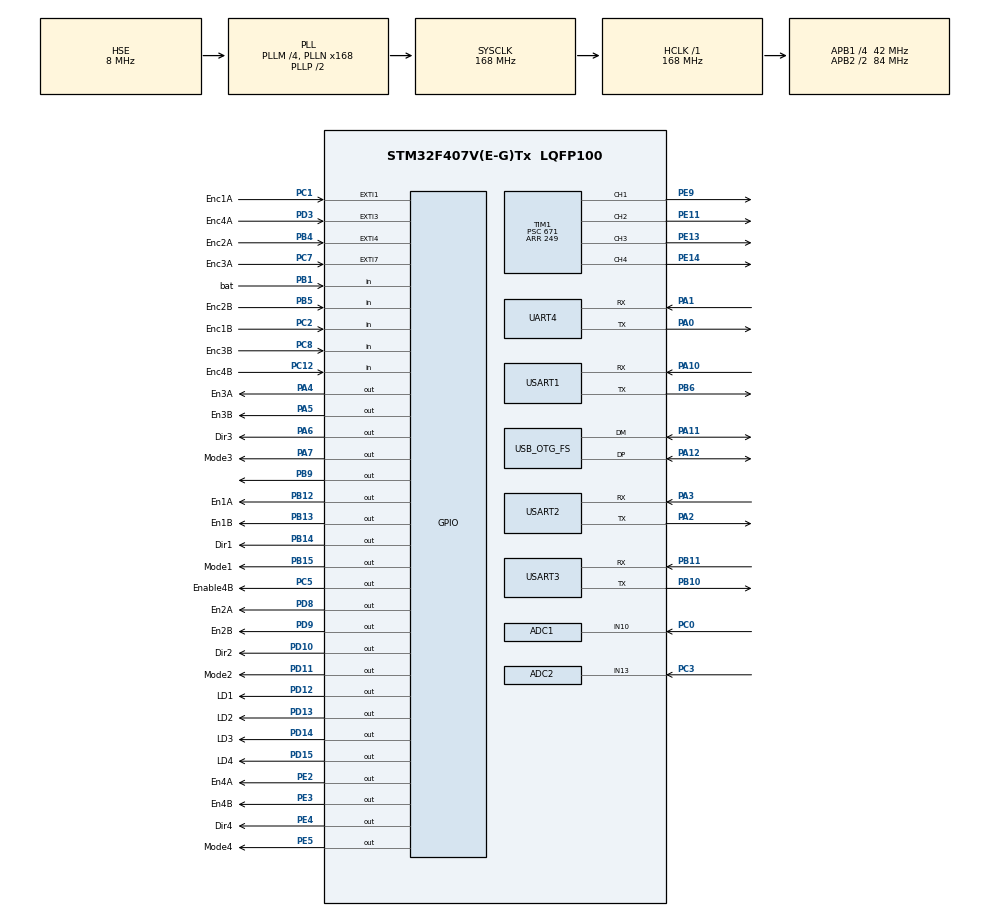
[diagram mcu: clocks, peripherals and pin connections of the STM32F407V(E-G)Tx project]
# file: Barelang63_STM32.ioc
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ADC1.Channel-5\#ChannelRegularConversion=ADC_CHANNEL_10
ADC1.ContinuousConvMode=DISABLE
ADC1.NbrOfConversionFlag=1
ADC1.Rank-5\#ChannelRegularConversion=1
ADC1.SamplingTime-5\#ChannelRegularConversion=ADC_SAMPLETIME_3CYCLES
ADC1.master=1
ADC2.Channel-0\#ChannelRegularConversion=ADC_CHANNEL_13
ADC2.NbrOfConversion=1
ADC2.NbrOfConversionFlag=1
ADC2.Rank-0\#ChannelRegularConversion=1
ADC2.SamplingTime-0\#ChannelRegularConversion=ADC_SAMPLETIME_3CYCLES
Dma.ADC1.4.Direction=DMA_PERIPH_TO_MEMORY
Dma.ADC1.4.FIFOMode=DMA_FIFOMODE_DISABLE
Dma.ADC1.4.Instance=DMA2_Stream0
Dma.ADC1.4.MemDataAlignment=DMA_MDATAALIGN_WORD
Dma.ADC1.4.MemInc=DMA_MINC_ENABLE
Dma.ADC1.4.Mode=DMA_CIRCULAR
Dma.ADC1.4.PeriphDataAlignment=DMA_PDATAALIGN_WORD
Dma.ADC1.4.PeriphInc=DMA_PINC_DISABLE
Dma.ADC1.4.Priority=DMA_PRIORITY_LOW
Dma.ADC2.5.Direction=DMA_PERIPH_TO_MEMORY
Dma.ADC2.5.FIFOMode=DMA_FIFOMODE_DISABLE
Dma.ADC2.5.Instance=DMA2_Stream2
Dma.ADC2.5.MemDataAlignment=DMA_MDATAALIGN_WORD
Dma.ADC2.5.MemInc=DMA_MINC_ENABLE
Dma.ADC2.5.Mode=DMA_CIRCULAR
Dma.ADC2.5.PeriphDataAlignment=DMA_PDATAALIGN_WORD
Dma.ADC2.5.PeriphInc=DMA_PINC_DISABLE
Dma.ADC2.5.Priority=DMA_PRIORITY_LOW
Dma.Request0=USART3_RX
Dma.Request1=UART4_TX
Dma.Request2=UART4_RX
Dma.Request3=USART3_TX
Dma.Request4=ADC1
Dma.Request5=ADC2
Dma.Request6=USART1_RX
Dma.Request7=USART1_TX
Dma.Request8=USART2_RX
Dma.Request9=USART2_TX
Dma.UART4_RX.2.Direction=DMA_PERIPH_TO_MEMORY
Dma.UART4_RX.2.FIFOMode=DMA_FIFOMODE_DISABLE
Dma.UART4_RX.2.Instance=DMA1_Stream2
Dma.UART4_RX.2.MemDataAlignment=DMA_MDATAALIGN_BYTE
Dma.UART4_RX.2.MemInc=DMA_MINC_ENABLE
Dma.UART4_RX.2.Mode=DMA_NORMAL
Dma.UART4_RX.2.PeriphDataAlignment=DMA_PDATAALIGN_BYTE
Dma.UART4_RX.2.PeriphInc=DMA_PINC_DISABLE
Dma.UART4_RX.2.Priority=DMA_PRIORITY_LOW
Dma.UART4_TX.1.Direction=DMA_MEMORY_TO_PERIPH
Dma.UART4_TX.1.FIFOMode=DMA_FIFOMODE_DISABLE
Dma.UART4_TX.1.Instance=DMA1_Stream4
Dma.UART4_TX.1.MemDataAlignment=DMA_MDATAALIGN_BYTE
Dma.UART4_TX.1.MemInc=DMA_MINC_ENABLE
Dma.UART4_TX.1.Mode=DMA_NORMAL
Dma.UART4_TX.1.PeriphDataAlignment=DMA_PDATAALIGN_BYTE
Dma.UART4_TX.1.PeriphInc=DMA_PINC_DISABLE
Dma.UART4_TX.1.Priority=DMA_PRIORITY_LOW
Dma.USART1_RX.6.Direction=DMA_PERIPH_TO_MEMORY
Dma.USART1_RX.6.FIFOMode=DMA_FIFOMODE_DISABLE
Dma.USART1_RX.6.Instance=DMA2_Stream5
Dma.USART1_RX.6.MemDataAlignment=DMA_MDATAALIGN_BYTE
Dma.USART1_RX.6.MemInc=DMA_MINC_ENABLE
Dma.USART1_RX.6.Mode=DMA_NORMAL
Dma.USART1_RX.6.PeriphDataAlignment=DMA_PDATAALIGN_BYTE
Dma.USART1_RX.6.PeriphInc=DMA_PINC_DISABLE
Dma.USART1_RX.6.Priority=DMA_PRIORITY_LOW
Dma.USART1_TX.7.Direction=DMA_MEMORY_TO_PERIPH
Dma.USART1_TX.7.FIFOMode=DMA_FIFOMODE_DISABLE
Dma.USART1_TX.7.Instance=DMA2_Stream7
Dma.USART1_TX.7.MemDataAlignment=DMA_MDATAALIGN_BYTE
Dma.USART1_TX.7.MemInc=DMA_MINC_ENABLE
Dma.USART1_TX.7.Mode=DMA_NORMAL
Dma.USART1_TX.7.PeriphDataAlignment=DMA_PDATAALIGN_BYTE
Dma.USART1_TX.7.PeriphInc=DMA_PINC_DISABLE
Dma.USART1_TX.7.Priority=DMA_PRIORITY_LOW
Dma.USART2_RX.8.Direction=DMA_PERIPH_TO_MEMORY
Dma.USART2_RX.8.FIFOMode=DMA_FIFOMODE_DISABLE
Dma.USART2_RX.8.Instance=DMA1_Stream5
Dma.USART2_RX.8.MemDataAlignment=DMA_MDATAALIGN_BYTE
Dma.USART2_RX.8.MemInc=DMA_MINC_ENABLE
Dma.USART2_RX.8.Mode=DMA_NORMAL
Dma.USART2_RX.8.PeriphDataAlignment=DMA_PDATAALIGN_BYTE
Dma.USART2_RX.8.PeriphInc=DMA_PINC_DISABLE
Dma.USART2_RX.8.Priority=DMA_PRIORITY_LOW
Dma.USART2_TX.9.Direction=DMA_MEMORY_TO_PERIPH
Dma.USART2_TX.9.FIFOMode=DMA_FIFOMODE_DISABLE
Dma.USART2_TX.9.Instance=DMA1_Stream6
Dma.USART2_TX.9.MemDataAlignment=DMA_MDATAALIGN_BYTE
Dma.USART2_TX.9.MemInc=DMA_MINC_ENABLE
Dma.USART2_TX.9.Mode=DMA_NORMAL
Dma.USART2_TX.9.PeriphDataAlignment=DMA_PDATAALIGN_BYTE
Dma.USART2_TX.9.PeriphInc=DMA_PINC_DISABLE
Dma.USART2_TX.9.Priority=DMA_PRIORITY_LOW
Dma.USART3_RX.0.Direction=DMA_PERIPH_TO_MEMORY
Dma.USART3_RX.0.FIFOMode=DMA_FIFOMODE_DISABLE
Dma.USART3_RX.0.Instance=DMA1_Stream1
Dma.USART3_RX.0.MemDataAlignment=DMA_MDATAALIGN_BYTE
Dma.USART3_RX.0.MemInc=DMA_MINC_ENABLE
Dma.USART3_RX.0.Mode=DMA_NORMAL
Dma.USART3_RX.0.PeriphDataAlignment=DMA_PDATAALIGN_BYTE
Dma.USART3_RX.0.PeriphInc=DMA_PINC_DISABLE
Dma.USART3_RX.0.Priority=DMA_PRIORITY_LOW
Dma.USART3_TX.3.Direction=DMA_MEMORY_TO_PERIPH
Dma.USART3_TX.3.FIFOMode=DMA_FIFOMODE_DISABLE
Dma.USART3_TX.3.Instance=DMA1_Stream3
Dma.USART3_TX.3.MemDataAlignment=DMA_MDATAALIGN_BYTE
Dma.USART3_TX.3.MemInc=DMA_MINC_ENABLE
Dma.USART3_TX.3.Mode=DMA_NORMAL
Dma.USART3_TX.3.PeriphDataAlignment=DMA_PDATAALIGN_BYTE
Dma.USART3_TX.3.PeriphInc=DMA_PINC_DISABLE
Dma.USART3_TX.3.Priority=DMA_PRIORITY_LOW
Mcu.Family=STM32F4
Mcu.Name=STM32F407V(E-G)Tx
Mcu.Package=LQFP100
NVIC.ADC_IRQn=true\:0\:0\:false\:false\:true\:true\:true
NVIC.DMA1_Stream1_IRQn=true\:0\:0\:false\:false\:true\:false\:true
NVIC.DMA1_Stream2_IRQn=true\:0\:0\:false\:false\:true\:false\:true
NVIC.DMA1_Stream3_IRQn=true\:0\:0\:false\:false\:true\:false\:true
NVIC.DMA1_Stream4_IRQn=true\:0\:0\:false\:false\:true\:false\:true
NVIC.DMA1_Stream5_IRQn=true\:0\:0\:false\:false\:true\:false\:true
NVIC.DMA1_Stream6_IRQn=true\:0\:0\:false\:false\:true\:false\:true
NVIC.DMA2_Stream0_IRQn=true\:0\:0\:false\:false\:true\:false\:true
NVIC.DMA2_Stream2_IRQn=true\:0\:0\:false\:false\:true\:false\:true
NVIC.DMA2_Stream5_IRQn=true\:0\:0\:false\:false\:true\:false\:true
NVIC.DMA2_Stream7_IRQn=true\:0\:0\:false\:false\:true\:false\:true
NVIC.EXTI1_IRQn=true\:0\:0\:false\:false\:true\:true\:true
NVIC.EXTI3_IRQn=true\:0\:0\:false\:false\:true\:true\:true
NVIC.EXTI4_IRQn=true\:0\:0\:false\:false\:true\:true\:true
NVIC.EXTI9_5_IRQn=true\:0\:0\:false\:false\:true\:true\:true
NVIC.OTG_FS_IRQn=true\:0\:0\:false\:false\:true\:false\:true
NVIC.PriorityGroup=NVIC_PRIORITYGROUP_0
NVIC.TIM1_UP_TIM10_IRQn=true\:0\:0\:false\:false\:true\:true\:true
NVIC.TIM2_IRQn=true\:0\:0\:false\:false\:true\:true\:true
NVIC.UART4_IRQn=true\:0\:0\:false\:false\:true\:true\:true
NVIC.USART1_IRQn=true\:0\:0\:false\:false\:true\:true\:true
NVIC.USART2_IRQn=true\:0\:0\:false\:false\:true\:true\:true
NVIC.USART3_IRQn=true\:0\:0\:false\:false\:true\:true\:true
PA0-WKUP.Mode=Asynchronous
PA0-WKUP.Signal=UART4_TX
PA1.Mode=Asynchronous
PA1.Signal=UART4_RX
PA10.Mode=Asynchronous
PA10.Signal=USART1_RX
PA11.Mode=Device_Only
PA11.Signal=USB_OTG_FS_DM
PA12.Mode=Device_Only
PA12.Signal=USB_OTG_FS_DP
PA13.Mode=Serial_Wire
PA13.Signal=SYS_JTMS-SWDIO
PA14.Mode=Serial_Wire
PA14.Signal=SYS_JTCK-SWCLK
PA2.Mode=Asynchronous
PA2.Signal=USART2_TX
PA3.Mode=Asynchronous
PA3.Signal=USART2_RX
PA4.GPIO_Label=En3A
PA4.Signal=GPIO_Output
PA5.GPIO_Label=En3B
PA5.Signal=GPIO_Output
PA6.GPIO_Label=Dir3
PA6.Signal=GPIO_Output
PA7.GPIO_Label=Mode3
PA7.Signal=GPIO_Output
PB1.GPIO_Label=bat
PB1.GPIO_PuPd=GPIO_PULLDOWN
PB1.Signal=GPIO_Input
PB10.Mode=Asynchronous
PB10.Signal=USART3_TX
PB11.Mode=Asynchronous
PB11.Signal=USART3_RX
PB12.GPIO_Label=En1A
PB12.Signal=GPIO_Output
PB13.GPIO_Label=En1B
PB13.Signal=GPIO_Output
PB14.GPIO_Label=Dir1
PB14.Signal=GPIO_Output
PB15.GPIO_Label=Mode1
PB15.Signal=GPIO_Output
PB4.GPIO_Label=Enc2A
PB4.GPIO_PuPd=GPIO_PULLUP
PB4.Signal=GPXTI4
PB5.GPIO_Label=Enc2B
PB5.GPIO_PuPd=GPIO_PULLUP
PB5.Signal=GPIO_Input
PB6.Mode=Asynchronous
PB6.Signal=USART1_TX
PB9.Signal=GPIO_Output
PC0.Signal=ADCx_IN10
PC1.GPIO_Label=Enc1A
PC1.GPIO_ModeDefaultEXTI=GPIO_MODE_IT_RISING
PC1.GPIO_PuPd=GPIO_PULLUP
PC1.Signal=GPXTI1
PC12.GPIO_Label=Enc4B
PC12.GPIO_PuPd=GPIO_PULLUP
PC12.Signal=GPIO_Input
PC2.GPIO_Label=Enc1B
PC2.GPIO_PuPd=GPIO_PULLUP
PC2.Signal=GPIO_Input
PC3.Signal=ADCx_IN13
PC5.GPIO_Label=Enable4B
PC5.Signal=GPIO_Output
PC7.GPIO_Label=Enc3A
PC7.GPIO_ModeDefaultEXTI=GPIO_MODE_IT_RISING
PC7.GPIO_PuPd=GPIO_PULLUP
PC7.Signal=GPXTI7
PC8.GPIO_Label=Enc3B
PC8.GPIO_PuPd=GPIO_PULLUP
PC8.Signal=GPIO_Input
PD10.GPIO_Label=Dir2
PD10.Signal=GPIO_Output
PD11.GPIO_Label=Mode2
PD11.Signal=GPIO_Output
PD12.GPIO_Label=LD1
PD12.Signal=GPIO_Output
PD13.GPIO_Label=LD2
PD13.Signal=GPIO_Output
PD14.GPIO_Label=LD3
PD14.Signal=GPIO_Output
PD15.GPIO_Label=LD4
PD15.Signal=GPIO_Output
PD3.GPIO_Label=Enc4A
PD3.GPIO_ModeDefaultEXTI=GPIO_MODE_IT_RISING
PD3.GPIO_PuPd=GPIO_PULLUP
PD3.Signal=GPXTI3
PD8.GPIO_Label=En2A
PD8.Signal=GPIO_Output
PD9.GPIO_Label=En2B
PD9.Signal=GPIO_Output
PE11.Signal=S_TIM1_CH2
PE13.Signal=S_TIM1_CH3
PE14.Signal=S_TIM1_CH4
PE2.GPIO_Label=En4A
PE2.Signal=GPIO_Output
PE3.GPIO_Label=En4B
PE3.Signal=GPIO_Output
PE4.GPIO_Label=Dir4
PE4.Signal=GPIO_Output
PE5.GPIO_Label=Mode4
PE5.Signal=GPIO_Output
PE9.Signal=S_TIM1_CH1
PH0-OSC_IN.Mode=HSE-External-Oscillator
PH0-OSC_IN.Signal=RCC_OSC_IN
PH1-OSC_OUT.Mode=HSE-External-Oscillator
PH1-OSC_OUT.Signal=RCC_OSC_OUT
ProjectManager.HeapSize=0x200
ProjectManager.StackSize=0x400
ProjectManager.TargetToolchain=STM32CubeIDE
RCC.48MHZClocksFreq_Value=48000000
RCC.AHBFreq_Value=168000000
RCC.APB1CLKDivider=RCC_HCLK_DIV4
RCC.APB1Freq_Value=42000000
RCC.APB1TimFreq_Value=84000000
RCC.APB2CLKDivider=RCC_HCLK_DIV2
RCC.APB2Freq_Value=84000000
RCC.APB2TimFreq_Value=168000000
RCC.CortexFreq_Value=168000000
RCC.HCLKFreq_Value=168000000
RCC.HSE_VALUE=8000000
RCC.HSI_VALUE=16000000
RCC.LSE_VALUE=32768
RCC.PLLM=4
RCC.PLLN=168
RCC.PLLQ=7
RCC.SYSCLKFreq_VALUE=168000000
RCC.SYSCLKSource=RCC_SYSCLKSOURCE_PLLCLK
RCC.VCOOutputFreq_Value=336000000
SH.ADCx_IN10.0=ADC1_IN10,IN10
SH.ADCx_IN13.0=ADC2_IN13,IN13
SH.S_TIM1_CH1.0=TIM1_CH1,PWM Generation1 CH1
SH.S_TIM1_CH2.0=TIM1_CH2,PWM Generation2 CH2
SH.S_TIM1_CH3.0=TIM1_CH3,PWM Generation3 CH3
SH.S_TIM1_CH4.0=TIM1_CH4,PWM Generation4 CH4
TIM1.Channel-PWM\ Generation1\ CH1=TIM_CHANNEL_1
TIM1.Channel-PWM\ Generation2\ CH2=TIM_CHANNEL_2
TIM1.Channel-PWM\ Generation3\ CH3=TIM_CHANNEL_3
TIM1.Channel-PWM\ Generation4\ CH4=TIM_CHANNEL_4
TIM1.Period=249
TIM1.Prescaler=671
TIM2.Period=34
TIM2.Prescaler=23
UART4.VirtualMode=Asynchronous
USART1.VirtualMode=VM_ASYNC
USART2.VirtualMode=VM_ASYNC
USART3.VirtualMode=VM_ASYNC
USB_DEVICE.CLASS_NAME_FS=CDC
USB_DEVICE.VirtualMode-CDC_FS=Cdc
USB_DEVICE.VirtualModeFS=Cdc_FS
USB_OTG_FS.VirtualMode=Device_Only
VP_TIM1_VS_ClockSourceINT.Mode=Internal
VP_TIM2_VS_ClockSourceINT.Mode=Internal
VP_USB_DEVICE_VS_USB_DEVICE_CDC_FS.Mode=CDC_FS
board=STM32F407G-DISC1

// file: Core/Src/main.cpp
/* USER CODE BEGIN Header */
/**
  ******************************************************************************
  * @file           : main.c
  * @brief          : Main program body
  ******************************************************************************
  * @attention
  *
  * Copyright (c) 2023 STMicroelectronics.
  * All rights reserved.
  *
  * This software is licensed under terms that can be found in the LICENSE file
  * in the root directory of this software component.
  * If no LICENSE file comes with this software, it is provided AS-IS.
  *
  ******************************************************************************
  */
/* USER CODE END Header */
#include "main.h"
#include "usb_device.h"

/* USER CODE BEGIN Includes */
#include "usbd_cdc_if.h"
#include "stdio.h"
#include "string.h"
#include "motor.h"
#include "mainpp.h"
#include "IMU_GY25.h"
//#include "mainppVoid.h"
/* USER CODE END Includes */

ADC_HandleTypeDef hadc1;
ADC_HandleTypeDef hadc2;
DMA_HandleTypeDef hdma_adc1;
DMA_HandleTypeDef hdma_adc2;

TIM_HandleTypeDef htim1;
TIM_HandleTypeDef htim2;

UART_HandleTypeDef huart4;
UART_HandleTypeDef huart1;
UART_HandleTypeDef huart2;
UART_HandleTypeDef huart3;
DMA_HandleTypeDef hdma_uart4_tx;
DMA_HandleTypeDef hdma_uart4_rx;
DMA_HandleTypeDef hdma_usart1_rx;
DMA_HandleTypeDef hdma_usart1_tx;
DMA_HandleTypeDef hdma_usart2_rx;
DMA_HandleTypeDef hdma_usart2_tx;
DMA_HandleTypeDef hdma_usart3_rx;
DMA_HandleTypeDef hdma_usart3_tx;

void SystemClock_Config(void);
static void MX_GPIO_Init(void);
static void MX_DMA_Init(void);
static void MX_TIM1_Init(void);
static void MX_TIM2_Init(void);
static void MX_USART3_UART_Init(void);
static void MX_UART4_Init(void);
static void MX_USART2_UART_Init(void);
static void MX_ADC1_Init(void);
static void MX_ADC2_Init(void);
static void MX_USART1_UART_Init(void);

int main(void)
{

  /* MCU Configuration--------------------------------------------------------*/

  /* Reset of all peripherals, Initializes the Flash interface and the Systick. */
  HAL_Init();

  /* Configure the system clock */
  SystemClock_Config();

  /* Initialize all configured peripherals */
  MX_GPIO_Init();
  MX_DMA_Init();
  MX_TIM1_Init();
  MX_TIM2_Init();
  MX_USART3_UART_Init();
  MX_UART4_Init();
  MX_USB_DEVICE_Init();
  MX_USART2_UART_Init();
  MX_ADC1_Init();
  MX_ADC2_Init();
  MX_USART1_UART_Init();
  /* USER CODE BEGIN 2 */
  init();

  /* USER CODE END 2 */

  /* Infinite loop */
  /* USER CODE BEGIN WHILE */
  while (1)
  {
	  loop();

    /* USER CODE END WHILE */

  }
}

void SystemClock_Config(void)
{
  RCC_OscInitTypeDef RCC_OscInitStruct = {0};
  RCC_ClkInitTypeDef RCC_ClkInitStruct = {0};

  /** Configure the main internal regulator output voltage
  */
  __HAL_RCC_PWR_CLK_ENABLE();
  __HAL_PWR_VOLTAGESCALING_CONFIG(PWR_REGULATOR_VOLTAGE_SCALE1);
  /** Initializes the RCC Oscillators according to the specified parameters
  * in the RCC_OscInitTypeDef structure.
  */
  RCC_OscInitStruct.OscillatorType = RCC_OSCILLATORTYPE_HSE;
  RCC_OscInitStruct.HSEState = RCC_HSE_ON;
  RCC_OscInitStruct.PLL.PLLState = RCC_PLL_ON;
  RCC_OscInitStruct.PLL.PLLSource = RCC_PLLSOURCE_HSE;
  RCC_OscInitStruct.PLL.PLLM = 4;
  RCC_OscInitStruct.PLL.PLLN = 168;
  RCC_OscInitStruct.PLL.PLLP = RCC_PLLP_DIV2;
  RCC_OscInitStruct.PLL.PLLQ = 7;
  if (HAL_RCC_OscConfig(&RCC_OscInitStruct) != HAL_OK)
  {
    Error_Handler();
  }
  /** Initializes the CPU, AHB and APB buses clocks
  */
  RCC_ClkInitStruct.ClockType = RCC_CLOCKTYPE_HCLK|RCC_CLOCKTYPE_SYSCLK
                              |RCC_CLOCKTYPE_PCLK1|RCC_CLOCKTYPE_PCLK2;
  RCC_ClkInitStruct.SYSCLKSource = RCC_SYSCLKSOURCE_PLLCLK;
  RCC_ClkInitStruct.AHBCLKDivider = RCC_SYSCLK_DIV1;
  RCC_ClkInitStruct.APB1CLKDivider = RCC_HCLK_DIV4;
  RCC_ClkInitStruct.APB2CLKDivider = RCC_HCLK_DIV2;

  if (HAL_RCC_ClockConfig(&RCC_ClkInitStruct, FLASH_LATENCY_5) != HAL_OK)
  {
    Error_Handler();
  }
}

static void MX_ADC1_Init(void)
{

  ADC_ChannelConfTypeDef sConfig = {0};

  /** Configure the global features of the ADC (Clock, Resolution, Data Alignment and number of conversion)
  */
  hadc1.Instance = ADC1;
  hadc1.Init.ClockPrescaler = ADC_CLOCK_SYNC_PCLK_DIV4;
  hadc1.Init.Resolution = ADC_RESOLUTION_12B;
  hadc1.Init.ScanConvMode = DISABLE;
  hadc1.Init.ContinuousConvMode = DISABLE;
  hadc1.Init.DiscontinuousConvMode = DISABLE;
  hadc1.Init.ExternalTrigConvEdge = ADC_EXTERNALTRIGCONVEDGE_NONE;
  hadc1.Init.ExternalTrigConv = ADC_SOFTWARE_START;
  hadc1.Init.DataAlign = ADC_DATAALIGN_RIGHT;
  hadc1.Init.NbrOfConversion = 1;
  hadc1.Init.DMAContinuousRequests = DISABLE;
  hadc1.Init.EOCSelection = ADC_EOC_SINGLE_CONV;
  if (HAL_ADC_Init(&hadc1) != HAL_OK)
  {
    Error_Handler();
  }
  /** Configure for the selected ADC regular channel its corresponding rank in the sequencer and its sample time.
  */
  sConfig.Channel = ADC_CHANNEL_10;
  sConfig.Rank = 1;
  sConfig.SamplingTime = ADC_SAMPLETIME_3CYCLES;
  if (HAL_ADC_ConfigChannel(&hadc1, &sConfig) != HAL_OK)
  {
    Error_Handler();
  }

}

static void MX_ADC2_Init(void)
{

  ADC_ChannelConfTypeDef sConfig = {0};

  /** Configure the global features of the ADC (Clock, Resolution, Data Alignment and number of conversion)
  */
  hadc2.Instance = ADC2;
  hadc2.Init.ClockPrescaler = ADC_CLOCK_SYNC_PCLK_DIV4;
  hadc2.Init.Resolution = ADC_RESOLUTION_12B;
  hadc2.Init.ScanConvMode = DISABLE;
  hadc2.Init.ContinuousConvMode = DISABLE;
  hadc2.Init.DiscontinuousConvMode = DISABLE;
  hadc2.Init.ExternalTrigConvEdge = ADC_EXTERNALTRIGCONVEDGE_NONE;
  hadc2.Init.ExternalTrigConv = ADC_SOFTWARE_START;
  hadc2.Init.DataAlign = ADC_DATAALIGN_RIGHT;
  hadc2.Init.NbrOfConversion = 1;
  hadc2.Init.DMAContinuousRequests = DISABLE;
  hadc2.Init.EOCSelection = ADC_EOC_SINGLE_CONV;
  if (HAL_ADC_Init(&hadc2) != HAL_OK)
  {
    Error_Handler();
  }
  /** Configure for the selected ADC regular channel its corresponding rank in the sequencer and its sample time.
  */
  sConfig.Channel = ADC_CHANNEL_13;
  sConfig.Rank = 1;
  sConfig.SamplingTime = ADC_SAMPLETIME_3CYCLES;
  if (HAL_ADC_ConfigChannel(&hadc2, &sConfig) != HAL_OK)
  {
    Error_Handler();
  }

}

static void MX_TIM1_Init(void)
{

  TIM_ClockConfigTypeDef sClockSourceConfig = {0};
  TIM_MasterConfigTypeDef sMasterConfig = {0};
  TIM_OC_InitTypeDef sConfigOC = {0};
  TIM_BreakDeadTimeConfigTypeDef sBreakDeadTimeConfig = {0};

  htim1.Instance = TIM1;
  htim1.Init.Prescaler = 671;
  htim1.Init.CounterMode = TIM_COUNTERMODE_UP;
  htim1.Init.Period = 249;
  htim1.Init.ClockDivision = TIM_CLOCKDIVISION_DIV1;
  htim1.Init.RepetitionCounter = 0;
  htim1.Init.AutoReloadPreload = TIM_AUTORELOAD_PRELOAD_DISABLE;
  if (HAL_TIM_Base_Init(&htim1) != HAL_OK)
  {
    Error_Handler();
  }
  sClockSourceConfig.ClockSource = TIM_CLOCKSOURCE_INTERNAL;
  if (HAL_TIM_ConfigClockSource(&htim1, &sClockSourceConfig) != HAL_OK)
  {
    Error_Handler();
  }
  if (HAL_TIM_PWM_Init(&htim1) != HAL_OK)
  {
    Error_Handler();
  }
  sMasterConfig.MasterOutputTrigger = TIM_TRGO_RESET;
  sMasterConfig.MasterSlaveMode = TIM_MASTERSLAVEMODE_DISABLE;
  if (HAL_TIMEx_MasterConfigSynchronization(&htim1, &sMasterConfig) != HAL_OK)
  {
    Error_Handler();
  }
  sConfigOC.OCMode = TIM_OCMODE_PWM1;
  sConfigOC.Pulse = 0;
  sConfigOC.OCPolarity = TIM_OCPOLARITY_HIGH;
  sConfigOC.OCNPolarity = TIM_OCNPOLARITY_HIGH;
  sConfigOC.OCFastMode = TIM_OCFAST_DISABLE;
  sConfigOC.OCIdleState = TIM_OCIDLESTATE_RESET;
  sConfigOC.OCNIdleState = TIM_OCNIDLESTATE_RESET;
  if (HAL_TIM_PWM_ConfigChannel(&htim1, &sConfigOC, TIM_CHANNEL_1) != HAL_OK)
  {
    Error_Handler();
  }
  if (HAL_TIM_PWM_ConfigChannel(&htim1, &sConfigOC, TIM_CHANNEL_2) != HAL_OK)
  {
    Error_Handler();
  }
  if (HAL_TIM_PWM_ConfigChannel(&htim1, &sConfigOC, TIM_CHANNEL_3) != HAL_OK)
  {
    Error_Handler();
  }
  if (HAL_TIM_PWM_ConfigChannel(&htim1, &sConfigOC, TIM_CHANNEL_4) != HAL_OK)
  {
    Error_Handler();
  }
  sBreakDeadTimeConfig.OffStateRunMode = TIM_OSSR_DISABLE;
  sBreakDeadTimeConfig.OffStateIDLEMode = TIM_OSSI_DISABLE;
  sBreakDeadTimeConfig.LockLevel = TIM_LOCKLEVEL_OFF;
  sBreakDeadTimeConfig.DeadTime = 0;
  sBreakDeadTimeConfig.BreakState = TIM_BREAK_DISABLE;
  sBreakDeadTimeConfig.BreakPolarity = TIM_BREAKPOLARITY_HIGH;
  sBreakDeadTimeConfig.AutomaticOutput = TIM_AUTOMATICOUTPUT_DISABLE;
  if (HAL_TIMEx_ConfigBreakDeadTime(&htim1, &sBreakDeadTimeConfig) != HAL_OK)
  {
    Error_Handler();
  }
  /* USER CODE BEGIN TIM1_Init 2 */
	HAL_TIM_PWM_Start(&htim1, TIM_CHANNEL_1);
	HAL_TIM_PWM_Start(&htim1, TIM_CHANNEL_2);
	HAL_TIM_PWM_Start(&htim1, TIM_CHANNEL_3);
	HAL_TIM_PWM_Start(&htim1, TIM_CHANNEL_4);
  /* USER CODE END TIM1_Init 2 */
  HAL_TIM_MspPostInit(&htim1);

}

static void MX_TIM2_Init(void)
{

  TIM_ClockConfigTypeDef sClockSourceConfig = {0};
  TIM_MasterConfigTypeDef sMasterConfig = {0};

  htim2.Instance = TIM2;
  htim2.Init.Prescaler = 23;
  htim2.Init.CounterMode = TIM_COUNTERMODE_UP;
  htim2.Init.Period = 34;
  htim2.Init.ClockDivision = TIM_CLOCKDIVISION_DIV1;
  htim2.Init.AutoReloadPreload = TIM_AUTORELOAD_PRELOAD_DISABLE;
  if (HAL_TIM_Base_Init(&htim2) != HAL_OK)
  {
    Error_Handler();
  }
  sClockSourceConfig.ClockSource = TIM_CLOCKSOURCE_INTERNAL;
  if (HAL_TIM_ConfigClockSource(&htim2, &sClockSourceConfig) != HAL_OK)
  {
    Error_Handler();
  }
  sMasterConfig.MasterOutputTrigger = TIM_TRGO_RESET;
  sMasterConfig.MasterSlaveMode = TIM_MASTERSLAVEMODE_DISABLE;
  if (HAL_TIMEx_MasterConfigSynchronization(&htim2, &sMasterConfig) != HAL_OK)
  {
    Error_Handler();
  }

}

static void MX_UART4_Init(void)
{

  huart4.Instance = UART4;
  huart4.Init.BaudRate = 115200;
  huart4.Init.WordLength = UART_WORDLENGTH_8B;
  huart4.Init.StopBits = UART_STOPBITS_1;
  huart4.Init.Parity = UART_PARITY_NONE;
  huart4.Init.Mode = UART_MODE_TX_RX;
  huart4.Init.HwFlowCtl = UART_HWCONTROL_NONE;
  huart4.Init.OverSampling = UART_OVERSAMPLING_16;
  if (HAL_UART_Init(&huart4) != HAL_OK)
  {
    Error_Handler();
  }

}

static void MX_USART1_UART_Init(void)
{

  huart1.Instance = USART1;
  huart1.Init.BaudRate = 115200;
  huart1.Init.WordLength = UART_WORDLENGTH_8B;
  huart1.Init.StopBits = UART_STOPBITS_1;
  huart1.Init.Parity = UART_PARITY_NONE;
  huart1.Init.Mode = UART_MODE_TX_RX;
  huart1.Init.HwFlowCtl = UART_HWCONTROL_NONE;
  huart1.Init.OverSampling = UART_OVERSAMPLING_16;
  if (HAL_UART_Init(&huart1) != HAL_OK)
  {
    Error_Handler();
  }

}

static void MX_USART2_UART_Init(void)
{

  huart2.Instance = USART2;
  huart2.Init.BaudRate = 115200;
  huart2.Init.WordLength = UART_WORDLENGTH_8B;
  huart2.Init.StopBits = UART_STOPBITS_1;
  huart2.Init.Parity = UART_PARITY_NONE;
  huart2.Init.Mode = UART_MODE_TX_RX;
  huart2.Init.HwFlowCtl = UART_HWCONTROL_NONE;
  huart2.Init.OverSampling = UART_OVERSAMPLING_16;
  if (HAL_UART_Init(&huart2) != HAL_OK)
  {
    Error_Handler();
  }

}

static void MX_USART3_UART_Init(void)
{

  huart3.Instance = USART3;
  huart3.Init.BaudRate = 115200;
  huart3.Init.WordLength = UART_WORDLENGTH_8B;
  huart3.Init.StopBits = UART_STOPBITS_1;
  huart3.Init.Parity = UART_PARITY_NONE;
  huart3.Init.Mode = UART_MODE_TX_RX;
  huart3.Init.HwFlowCtl = UART_HWCONTROL_NONE;
  huart3.Init.OverSampling = UART_OVERSAMPLING_16;
  if (HAL_UART_Init(&huart3) != HAL_OK)
  {
    Error_Handler();
  }

}

static void MX_DMA_Init(void)
{

  /* DMA controller clock enable */
  __HAL_RCC_DMA1_CLK_ENABLE();
  __HAL_RCC_DMA2_CLK_ENABLE();

  /* DMA interrupt init */
  /* DMA1_Stream1_IRQn interrupt configuration */
  HAL_NVIC_SetPriority(DMA1_Stream1_IRQn, 0, 0);
  HAL_NVIC_EnableIRQ(DMA1_Stream1_IRQn);
  /* DMA1_Stream2_IRQn interrupt configuration */
  HAL_NVIC_SetPriority(DMA1_Stream2_IRQn, 0, 0);
  HAL_NVIC_EnableIRQ(DMA1_Stream2_IRQn);
  /* DMA1_Stream3_IRQn interrupt configuration */
  HAL_NVIC_SetPriority(DMA1_Stream3_IRQn, 0, 0);
  HAL_NVIC_EnableIRQ(DMA1_Stream3_IRQn);
  /* DMA1_Stream4_IRQn interrupt configuration */
  HAL_NVIC_SetPriority(DMA1_Stream4_IRQn, 0, 0);
  HAL_NVIC_EnableIRQ(DMA1_Stream4_IRQn);
  /* DMA1_Stream5_IRQn interrupt configuration */
  HAL_NVIC_SetPriority(DMA1_Stream5_IRQn, 0, 0);
  HAL_NVIC_EnableIRQ(DMA1_Stream5_IRQn);
  /* DMA1_Stream6_IRQn interrupt configuration */
  HAL_NVIC_SetPriority(DMA1_Stream6_IRQn, 0, 0);
  HAL_NVIC_EnableIRQ(DMA1_Stream6_IRQn);
  /* DMA2_Stream0_IRQn interrupt configuration */
  HAL_NVIC_SetPriority(DMA2_Stream0_IRQn, 0, 0);
  HAL_NVIC_EnableIRQ(DMA2_Stream0_IRQn);
  /* DMA2_Stream2_IRQn interrupt configuration */
  HAL_NVIC_SetPriority(DMA2_Stream2_IRQn, 0, 0);
  HAL_NVIC_EnableIRQ(DMA2_Stream2_IRQn);
  /* DMA2_Stream5_IRQn interrupt configuration */
  HAL_NVIC_SetPriority(DMA2_Stream5_IRQn, 0, 0);
  HAL_NVIC_EnableIRQ(DMA2_Stream5_IRQn);
  /* DMA2_Stream7_IRQn interrupt configuration */
  HAL_NVIC_SetPriority(DMA2_Stream7_IRQn, 0, 0);
  HAL_NVIC_EnableIRQ(DMA2_Stream7_IRQn);

}

static void MX_GPIO_Init(void)
{
  GPIO_InitTypeDef GPIO_InitStruct = {0};

  /* GPIO Ports Clock Enable */
  __HAL_RCC_GPIOE_CLK_ENABLE();
  __HAL_RCC_GPIOH_CLK_ENABLE();
  __HAL_RCC_GPIOC_CLK_ENABLE();
  __HAL_RCC_GPIOA_CLK_ENABLE();
  __HAL_RCC_GPIOB_CLK_ENABLE();
  __HAL_RCC_GPIOD_CLK_ENABLE();

  /*Configure GPIO pin Output Level */
  HAL_GPIO_WritePin(GPIOE, En4A_Pin|En4B_Pin|Dir4_Pin|Mode4_Pin, GPIO_PIN_RESET);

  /*Configure GPIO pin Output Level */
  HAL_GPIO_WritePin(GPIOA, En3A_Pin|En3B_Pin|Dir3_Pin|Mode3_Pin, GPIO_PIN_RESET);

  /*Configure GPIO pin Output Level */
  HAL_GPIO_WritePin(Enable4B_GPIO_Port, Enable4B_Pin, GPIO_PIN_RESET);

  /*Configure GPIO pin Output Level */
  HAL_GPIO_WritePin(GPIOB, En1A_Pin|En1B_Pin|Dir1_Pin|Mode1_Pin
                          |GPIO_PIN_9, GPIO_PIN_RESET);

  /*Configure GPIO pin Output Level */
  HAL_GPIO_WritePin(GPIOD, En2A_Pin|En2B_Pin|Dir2_Pin|Mode2_Pin
                          |LD1_Pin|LD2_Pin|LD3_Pin|LD4_Pin, GPIO_PIN_RESET);

  /*Configure GPIO pins : En4A_Pin En4B_Pin Dir4_Pin Mode4_Pin */
  GPIO_InitStruct.Pin = En4A_Pin|En4B_Pin|Dir4_Pin|Mode4_Pin;
  GPIO_InitStruct.Mode = GPIO_MODE_OUTPUT_PP;
  GPIO_InitStruct.Pull = GPIO_NOPULL;
  GPIO_InitStruct.Speed = GPIO_SPEED_FREQ_LOW;
  HAL_GPIO_Init(GPIOE, &GPIO_InitStruct);

  /*Configure GPIO pins : Enc1A_Pin Enc3A_Pin */
  GPIO_InitStruct.Pin = Enc1A_Pin|Enc3A_Pin;
  GPIO_InitStruct.Mode = GPIO_MODE_IT_RISING;
  GPIO_InitStruct.Pull = GPIO_PULLUP;
  HAL_GPIO_Init(GPIOC, &GPIO_InitStruct);

  /*Configure GPIO pins : Enc1B_Pin Enc3B_Pin Enc4B_Pin */
  GPIO_InitStruct.Pin = Enc1B_Pin|Enc3B_Pin|Enc4B_Pin;
  GPIO_InitStruct.Mode = GPIO_MODE_INPUT;
  GPIO_InitStruct.Pull = GPIO_PULLUP;
  HAL_GPIO_Init(GPIOC, &GPIO_InitStruct);

  /*Configure GPIO pins : En3A_Pin En3B_Pin Dir3_Pin Mode3_Pin */
  GPIO_InitStruct.Pin = En3A_Pin|En3B_Pin|Dir3_Pin|Mode3_Pin;
  GPIO_InitStruct.Mode = GPIO_MODE_OUTPUT_PP;
  GPIO_InitStruct.Pull = GPIO_NOPULL;
  GPIO_InitStruct.Speed = GPIO_SPEED_FREQ_LOW;
  HAL_GPIO_Init(GPIOA, &GPIO_InitStruct);

  /*Configure GPIO pin : Enable4B_Pin */
  GPIO_InitStruct.Pin = Enable4B_Pin;
  GPIO_InitStruct.Mode = GPIO_MODE_OUTPUT_PP;
  GPIO_InitStruct.Pull = GPIO_NOPULL;
  GPIO_InitStruct.Speed = GPIO_SPEED_FREQ_LOW;
  HAL_GPIO_Init(Enable4B_GPIO_Port, &GPIO_InitStruct);

  /*Configure GPIO pin : bat_Pin */
  GPIO_InitStruct.Pin = bat_Pin;
  GPIO_InitStruct.Mode = GPIO_MODE_INPUT;
  GPIO_InitStruct.Pull = GPIO_PULLDOWN;
  HAL_GPIO_Init(bat_GPIO_Port, &GPIO_InitStruct);

  /*Configure GPIO pins : En1A_Pin En1B_Pin Dir1_Pin Mode1_Pin
                           PB9 */
  GPIO_InitStruct.Pin = En1A_Pin|En1B_Pin|Dir1_Pin|Mode1_Pin
                          |GPIO_PIN_9;
  GPIO_InitStruct.Mode = GPIO_MODE_OUTPUT_PP;
  GPIO_InitStruct.Pull = GPIO_NOPULL;
  GPIO_InitStruct.Speed = GPIO_SPEED_FREQ_LOW;
  HAL_GPIO_Init(GPIOB, &GPIO_InitStruct);

  /*Configure GPIO pins : En2A_Pin En2B_Pin Dir2_Pin Mode2_Pin
                           LD1_Pin LD2_Pin LD3_Pin LD4_Pin */
  GPIO_InitStruct.Pin = En2A_Pin|En2B_Pin|Dir2_Pin|Mode2_Pin
                          |LD1_Pin|LD2_Pin|LD3_Pin|LD4_Pin;
  GPIO_InitStruct.Mode = GPIO_MODE_OUTPUT_PP;
  GPIO_InitStruct.Pull = GPIO_NOPULL;
  GPIO_InitStruct.Speed = GPIO_SPEED_FREQ_LOW;
  HAL_GPIO_Init(GPIOD, &GPIO_InitStruct);

  /*Configure GPIO pin : Enc4A_Pin */
  GPIO_InitStruct.Pin = Enc4A_Pin;
  GPIO_InitStruct.Mode = GPIO_MODE_IT_RISING;
  GPIO_InitStruct.Pull = GPIO_PULLUP;
  HAL_GPIO_Init(Enc4A_GPIO_Port, &GPIO_InitStruct);

  /*Configure GPIO pin : Enc2A_Pin */
  GPIO_InitStruct.Pin = Enc2A_Pin;
  GPIO_InitStruct.Mode = GPIO_MODE_IT_RISING;
  GPIO_InitStruct.Pull = GPIO_PULLUP;
  HAL_GPIO_Init(Enc2A_GPIO_Port, &GPIO_InitStruct);

  /*Configure GPIO pin : Enc2B_Pin */
  GPIO_InitStruct.Pin = Enc2B_Pin;
  GPIO_InitStruct.Mode = GPIO_MODE_INPUT;
  GPIO_InitStruct.Pull = GPIO_PULLUP;
  HAL_GPIO_Init(Enc2B_GPIO_Port, &GPIO_InitStruct);

  /* EXTI interrupt init*/
  HAL_NVIC_SetPriority(EXTI1_IRQn, 0, 0);
  HAL_NVIC_EnableIRQ(EXTI1_IRQn);

  HAL_NVIC_SetPriority(EXTI3_IRQn, 0, 0);
  HAL_NVIC_EnableIRQ(EXTI3_IRQn);

  HAL_NVIC_SetPriority(EXTI4_IRQn, 0, 0);
  HAL_NVIC_EnableIRQ(EXTI4_IRQn);

  HAL_NVIC_SetPriority(EXTI9_5_IRQn, 0, 0);
  HAL_NVIC_EnableIRQ(EXTI9_5_IRQn);

}

void Error_Handler(void)
{
  __disable_irq();
  while (1)
  {
  }
}
